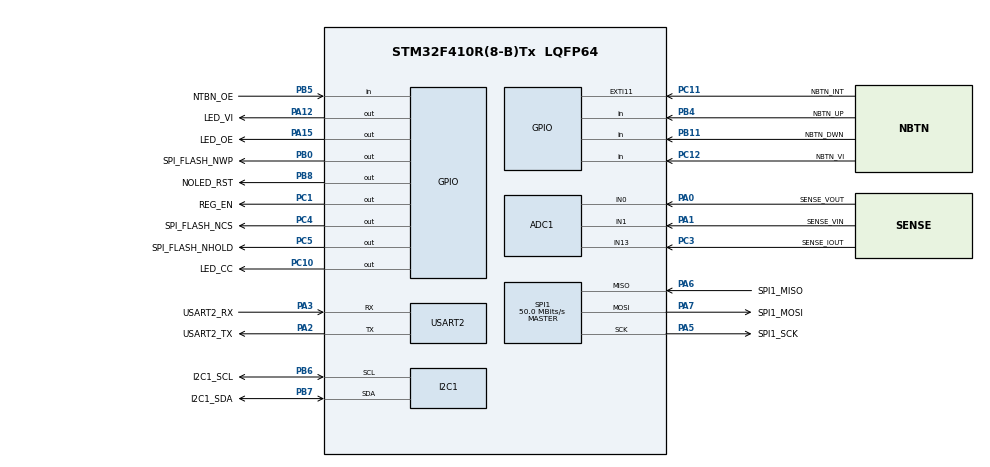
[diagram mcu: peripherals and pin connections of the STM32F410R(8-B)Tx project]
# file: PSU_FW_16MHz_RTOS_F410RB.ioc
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ADC1.Channel-0\#ChannelRegularConversion=ADC_CHANNEL_13
ADC1.Channel-1\#ChannelRegularConversion=ADC_CHANNEL_0
ADC1.Channel-2\#ChannelRegularConversion=ADC_CHANNEL_1
ADC1.Channel-3\#ChannelRegularConversion=ADC_CHANNEL_TEMPSENSOR
ADC1.Channel-4\#ChannelRegularConversion=ADC_CHANNEL_VREFINT
ADC1.ContinuousConvMode=ENABLE
ADC1.DMAContinuousRequests=ENABLE
ADC1.EOCSelection=ADC_EOC_SEQ_CONV
ADC1.EnableAnalogWatchDog=false
ADC1.NbrOfConversion=5
ADC1.NbrOfConversionFlag=1
ADC1.Rank-0\#ChannelRegularConversion=1
ADC1.Rank-1\#ChannelRegularConversion=2
ADC1.Rank-2\#ChannelRegularConversion=3
ADC1.Rank-3\#ChannelRegularConversion=4
ADC1.Rank-4\#ChannelRegularConversion=5
ADC1.SamplingTime-0\#ChannelRegularConversion=ADC_SAMPLETIME_56CYCLES
ADC1.SamplingTime-1\#ChannelRegularConversion=ADC_SAMPLETIME_56CYCLES
ADC1.SamplingTime-2\#ChannelRegularConversion=ADC_SAMPLETIME_56CYCLES
ADC1.SamplingTime-3\#ChannelRegularConversion=ADC_SAMPLETIME_56CYCLES
ADC1.SamplingTime-4\#ChannelRegularConversion=ADC_SAMPLETIME_56CYCLES
ADC1.master=1
Dma.ADC1.0.Direction=DMA_PERIPH_TO_MEMORY
Dma.ADC1.0.FIFOMode=DMA_FIFOMODE_DISABLE
Dma.ADC1.0.Instance=DMA2_Stream0
Dma.ADC1.0.MemDataAlignment=DMA_MDATAALIGN_HALFWORD
Dma.ADC1.0.MemInc=DMA_MINC_ENABLE
Dma.ADC1.0.Mode=DMA_NORMAL
Dma.ADC1.0.PeriphDataAlignment=DMA_PDATAALIGN_HALFWORD
Dma.ADC1.0.PeriphInc=DMA_PINC_DISABLE
Dma.ADC1.0.Priority=DMA_PRIORITY_HIGH
Dma.Request0=ADC1
Dma.Request1=SPI1_RX
Dma.Request2=SPI1_TX
Dma.SPI1_RX.1.Direction=DMA_PERIPH_TO_MEMORY
Dma.SPI1_RX.1.FIFOMode=DMA_FIFOMODE_DISABLE
Dma.SPI1_RX.1.Instance=DMA2_Stream2
Dma.SPI1_RX.1.MemDataAlignment=DMA_MDATAALIGN_BYTE
Dma.SPI1_RX.1.MemInc=DMA_MINC_ENABLE
Dma.SPI1_RX.1.Mode=DMA_NORMAL
Dma.SPI1_RX.1.PeriphDataAlignment=DMA_PDATAALIGN_BYTE
Dma.SPI1_RX.1.PeriphInc=DMA_PINC_DISABLE
Dma.SPI1_RX.1.Priority=DMA_PRIORITY_HIGH
Dma.SPI1_TX.2.Direction=DMA_MEMORY_TO_PERIPH
Dma.SPI1_TX.2.FIFOMode=DMA_FIFOMODE_DISABLE
Dma.SPI1_TX.2.Instance=DMA2_Stream3
Dma.SPI1_TX.2.MemDataAlignment=DMA_MDATAALIGN_BYTE
Dma.SPI1_TX.2.MemInc=DMA_MINC_ENABLE
Dma.SPI1_TX.2.Mode=DMA_NORMAL
Dma.SPI1_TX.2.PeriphDataAlignment=DMA_PDATAALIGN_BYTE
Dma.SPI1_TX.2.PeriphInc=DMA_PINC_DISABLE
Dma.SPI1_TX.2.Priority=DMA_PRIORITY_HIGH
FREERTOS.INCLUDE_pcTaskGetTaskName=1
FREERTOS.INCLUDE_vTaskDelayUntil=1
FREERTOS.MEMORY_ALLOCATION=2
FREERTOS.Tasks01=defaultTask,0,128,StartDefaultTask,Default,NULL,Dynamic,NULL,NULL
FREERTOS.configENABLE_FPU=1
FREERTOS.configTOTAL_HEAP_SIZE=15000
FREERTOS.configUSE_NEWLIB_REENTRANT=1
I2C1.I2C_Mode=I2C_Fast
Mcu.Family=STM32F4
Mcu.Name=STM32F410R(8-B)Tx
Mcu.Package=LQFP64
NVIC.DMA2_Stream0_IRQn=true\:5\:0\:false\:false\:true\:true\:false\:true
NVIC.DMA2_Stream2_IRQn=true\:5\:0\:false\:false\:true\:true\:false\:true
NVIC.DMA2_Stream3_IRQn=true\:5\:0\:false\:false\:true\:true\:false\:true
NVIC.PriorityGroup=NVIC_PRIORITYGROUP_4
NVIC.TIM6_DAC_IRQn=true\:15\:0\:false\:false\:true\:false\:false\:true
NVIC.TimeBase=TIM6_DAC_IRQn
NVIC.TimeBaseIP=TIM6
NVIC.USART2_IRQn=true\:5\:0\:false\:false\:true\:true\:true\:true
PA0-WKUP.GPIO_Label=SENSE_VOUT
PA0-WKUP.Signal=ADCx_IN0
PA1.GPIO_Label=SENSE_VIN
PA1.Signal=ADCx_IN1
PA12.GPIO_Label=LED_VI
PA12.Signal=GPIO_Output
PA13.GPIO_Label=SWDIO
PA13.Mode=Trace_Asynchronous_SW
PA13.Signal=SYS_JTMS-SWDIO
PA14.GPIO_Label=SWDCK
PA14.Mode=Trace_Asynchronous_SW
PA14.Signal=SYS_JTCK-SWCLK
PA15.GPIO_Label=LED_OE
PA15.Signal=GPIO_Output
PA2.GPIO_Label=USART2_TX
PA2.Mode=Asynchronous
PA2.Signal=USART2_TX
PA3.GPIO_Label=USART2_RX
PA3.Mode=Asynchronous
PA3.Signal=USART2_RX
PA5.GPIO_Label=SPI1_SCK
PA5.Mode=Full_Duplex_Master
PA5.Signal=SPI1_SCK
PA6.GPIO_Label=SPI1_MISO
PA6.Mode=Full_Duplex_Master
PA6.Signal=SPI1_MISO
PA7.GPIO_Label=SPI1_MOSI
PA7.Mode=Full_Duplex_Master
PA7.Signal=SPI1_MOSI
PB0.GPIO_Label=SPI_FLASH_NWP
PB0.Signal=GPIO_Output
PB11.GPIO_Label=NBTN_DWN
PB11.Signal=GPIO_Input
PB3.GPIO_Label=SWDO
PB3.Mode=Trace_Asynchronous_SW
PB3.Signal=SYS_JTDO-SWO
PB4.GPIO_Label=NBTN_UP
PB4.Signal=GPIO_Input
PB5.GPIO_Label=NTBN_OE
PB5.Signal=GPIO_Input
PB6.GPIO_Label=I2C1_SCL
PB6.Mode=I2C
PB6.Signal=I2C1_SCL
PB7.GPIO_Label=I2C1_SDA
PB7.Mode=I2C
PB7.Signal=I2C1_SDA
PB8.GPIO_Label=NOLED_RST
PB8.Signal=GPIO_Output
PC1.GPIO_Label=REG_EN
PC1.Signal=GPIO_Output
PC10.GPIO_Label=LED_CC
PC10.Signal=GPIO_Output
PC11.GPIO_Label=NBTN_INT
PC11.Signal=GPXTI11
PC12.GPIO_Label=NBTN_VI
PC12.Signal=GPIO_Input
PC3.GPIO_Label=SENSE_IOUT
PC3.Signal=ADCx_IN13
PC4.GPIO_Label=SPI_FLASH_NCS
PC4.Signal=GPIO_Output
PC5.GPIO_Label=SPI_FLASH_NHOLD
PC5.Signal=GPIO_Output
PH0\ -\ OSC_IN.GPIO_Label=HSE_IN
PH0\ -\ OSC_IN.Mode=HSE-External-Oscillator
PH0\ -\ OSC_IN.Signal=RCC_OSC_IN
PH1\ -\ OSC_OUT.GPIO_Label=HSE_OUT
PH1\ -\ OSC_OUT.Mode=HSE-External-Oscillator
PH1\ -\ OSC_OUT.Signal=RCC_OSC_OUT
ProjectManager.HeapSize=0x200
ProjectManager.StackSize=0x400
ProjectManager.TargetToolchain=STM32CubeIDE
RCC.48MHZClocksFreq_Value=50000000
RCC.AHBFreq_Value=100000000
RCC.APB1CLKDivider=RCC_HCLK_DIV2
RCC.APB1Freq_Value=50000000
RCC.APB1TimFreq_Value=100000000
RCC.APB2Freq_Value=100000000
RCC.APB2TimFreq_Value=100000000
RCC.CortexFreq_Value=100000000
RCC.HCLKFreq_Value=100000000
RCC.HSE_VALUE=16000000
RCC.HSI_VALUE=16000000
RCC.LSE_VALUE=32768
RCC.PLLM=8
RCC.PLLN=100
RCC.SYSCLKFreq_VALUE=100000000
RCC.SYSCLKSource=RCC_SYSCLKSOURCE_PLLCLK
RCC.VCOOutputFreq_Value=200000000
SH.ADCx_IN0.0=ADC1_IN0,IN0
SH.ADCx_IN1.0=ADC1_IN1,IN1
SH.ADCx_IN13.0=ADC1_IN13,IN13
SPI1.CalculateBaudRate=50.0 MBits/s
SPI1.Direction=SPI_DIRECTION_2LINES
SPI1.Mode=SPI_MODE_MASTER
SPI1.VirtualType=VM_MASTER
TIM11.Channel=TIM_CHANNEL_1
USART2.VirtualMode=VM_ASYNC
VP_ADC1_TempSens_Input.Mode=IN-TempSens
VP_ADC1_Vref_Input.Mode=IN-Vrefint
VP_CRC_VS_CRC.Mode=CRC_Activate
VP_FREERTOS_VS_CMSIS_V1.Mode=CMSIS_V1
VP_SYS_VS_tim6.Mode=TIM6
VP_TIM11_VS_ClockSourceINT.Mode=Enable_Timer
VP_TIM11_VS_no_output1.Mode=PWM Generation1 No Output
board=custom

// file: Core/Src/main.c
/* USER CODE BEGIN Header */
/**
  ******************************************************************************
  * @file           : main.c
  * @brief          : Main program body
  ******************************************************************************
  * @attention
  *
  * Copyright (c) 2022 STMicroelectronics.
  * All rights reserved.
  *
  * This software is licensed under terms that can be found in the LICENSE file
  * in the root directory of this software component.
  * If no LICENSE file comes with this software, it is provided AS-IS.
  *
  ******************************************************************************
  */
/* USER CODE END Header */
#include "main.h"
#include "cmsis_os.h"
#include "adc.h"
#include "crc.h"
#include "dma.h"
#include "i2c.h"
#include "spi.h"
#include "tim.h"
#include "usart.h"
#include "gpio.h"

void SystemClock_Config(void);
void MX_FREERTOS_Init(void);

int main(void)
{

  /* MCU Configuration--------------------------------------------------------*/

  /* Reset of all peripherals, Initializes the Flash interface and the Systick. */
  HAL_Init();

  /* Configure the system clock */
  SystemClock_Config();

  /* Initialize all configured peripherals */
  MX_GPIO_Init();
  MX_DMA_Init();
  MX_ADC1_Init();
  MX_I2C1_Init();
  MX_SPI1_Init();
  MX_USART2_UART_Init();
  MX_CRC_Init();
  MX_TIM11_Init();

  /* Call init function for freertos objects (in freertos.c) */
  MX_FREERTOS_Init();
  /* Start scheduler */
  osKernelStart();

  /* We should never get here as control is now taken by the scheduler */
  /* Infinite loop */
  while (1)
  {

  }
}

void SystemClock_Config(void)
{
  LL_FLASH_SetLatency(LL_FLASH_LATENCY_3);
  while(LL_FLASH_GetLatency()!= LL_FLASH_LATENCY_3)
  {
  }
  LL_PWR_SetRegulVoltageScaling(LL_PWR_REGU_VOLTAGE_SCALE1);
  LL_RCC_HSI_SetCalibTrimming(16);
  LL_RCC_HSI_Enable();

   /* Wait till HSI is ready */
  while(LL_RCC_HSI_IsReady() != 1)
  {

  }
  LL_RCC_PLL_ConfigDomain_SYS(LL_RCC_PLLSOURCE_HSI, LL_RCC_PLLM_DIV_8, 100, LL_RCC_PLLP_DIV_2);
  LL_RCC_PLL_Enable();

   /* Wait till PLL is ready */
  while(LL_RCC_PLL_IsReady() != 1)
  {

  }
  LL_RCC_SetAHBPrescaler(LL_RCC_SYSCLK_DIV_1);
  LL_RCC_SetAPB1Prescaler(LL_RCC_APB1_DIV_2);
  LL_RCC_SetAPB2Prescaler(LL_RCC_APB2_DIV_1);
  LL_RCC_SetSysClkSource(LL_RCC_SYS_CLKSOURCE_PLL);

   /* Wait till System clock is ready */
  while(LL_RCC_GetSysClkSource() != LL_RCC_SYS_CLKSOURCE_STATUS_PLL)
  {

  }
  LL_SetSystemCoreClock(100000000);

   /* Update the time base */
  if (HAL_InitTick (TICK_INT_PRIORITY) != HAL_OK)
  {
    Error_Handler();
  }
  LL_RCC_SetTIMPrescaler(LL_RCC_TIM_PRESCALER_TWICE);
}

void HAL_TIM_PeriodElapsedCallback(TIM_HandleTypeDef *htim)
{
  if (htim->Instance == TIM6) {
    HAL_IncTick();
  }
}

void Error_Handler(void)
{
  __disable_irq();
  while (1)
  {
  }
}

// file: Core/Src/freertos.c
/* USER CODE BEGIN Header */
/**
  ******************************************************************************
  * File Name          : freertos.c
  * Description        : Code for freertos applications
  ******************************************************************************
  * @attention
  *
  * Copyright (c) 2022 STMicroelectronics.
  * All rights reserved.
  *
  * This software is licensed under terms that can be found in the LICENSE file
  * in the root directory of this software component.
  * If no LICENSE file comes with this software, it is provided AS-IS.
  *
  ******************************************************************************
  */
/* USER CODE END Header */

#include "FreeRTOS.h"
#include "task.h"
#include "main.h"
#include "cmsis_os.h"

osThreadId defaultTaskHandle;

void StartDefaultTask(void const * argument);

void MX_FREERTOS_Init(void); /* (MISRA C 2004 rule 8.1) */

/* GetIdleTaskMemory prototype (linked to static allocation support) */
void vApplicationGetIdleTaskMemory( StaticTask_t **ppxIdleTaskTCBBuffer, StackType_t **ppxIdleTaskStackBuffer, uint32_t *pulIdleTaskStackSize );

/* USER CODE BEGIN GET_IDLE_TASK_MEMORY */
static StaticTask_t xIdleTaskTCBBuffer;
static StackType_t xIdleStack[configMINIMAL_STACK_SIZE];

void vApplicationGetIdleTaskMemory( StaticTask_t **ppxIdleTaskTCBBuffer, StackType_t **ppxIdleTaskStackBuffer, uint32_t *pulIdleTaskStackSize )
{
  *ppxIdleTaskTCBBuffer = &xIdleTaskTCBBuffer;
  *ppxIdleTaskStackBuffer = &xIdleStack[0];
  *pulIdleTaskStackSize = configMINIMAL_STACK_SIZE;
  /* place for user code */
}
/* USER CODE END GET_IDLE_TASK_MEMORY */

void MX_FREERTOS_Init(void) {

  /* Create the thread(s) */
  /* definition and creation of defaultTask */
  osThreadDef(defaultTask, StartDefaultTask, osPriorityNormal, 0, 128);
  defaultTaskHandle = osThreadCreate(osThread(defaultTask), NULL);

}

void StartDefaultTask(void const * argument)
{
  /* USER CODE BEGIN StartDefaultTask */
  /* Infinite loop */
  for(;;)
  {
	  LL_GPIO_TogglePin(LED_CC_GPIO_Port, LED_CC_Pin);
    osDelay(100);
  }
  /* USER CODE END StartDefaultTask */
}
